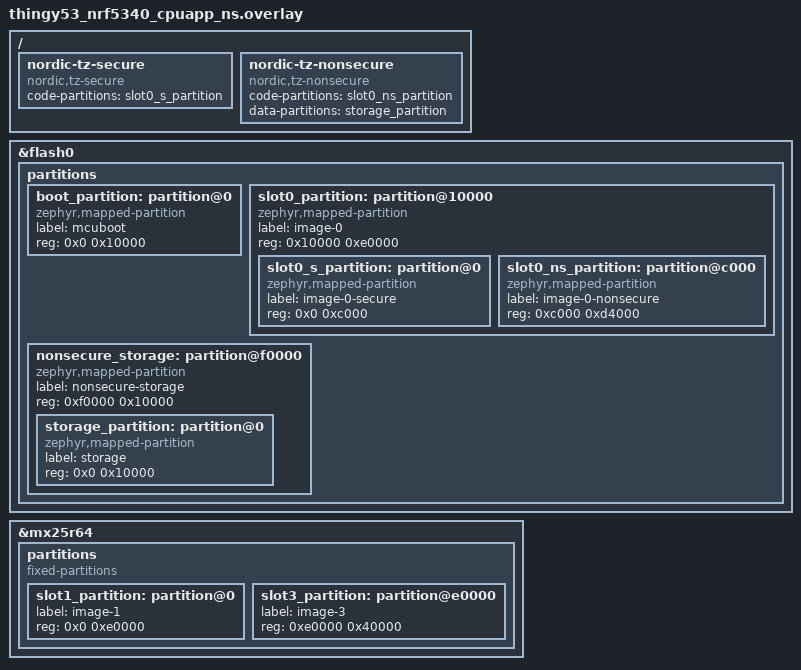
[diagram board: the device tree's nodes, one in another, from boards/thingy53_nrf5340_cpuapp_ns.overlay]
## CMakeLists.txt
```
#
# Copyright (c) 2023 Nordic Semiconductor
#
# SPDX-License-Identifier: LicenseRef-Nordic-5-Clause
#
cmake_minimum_required(VERSION 3.20.0)

find_package(Zephyr REQUIRED HINTS $ENV{ZEPHYR_BASE})
project(NONE)

# NORDIC SDK APP START
target_sources(app PRIVATE
  src/main.c
)

# NORDIC SDK APP END
```

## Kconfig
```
#
# Copyright (c) 2023 Nordic Semiconductor
#
# SPDX-License-Identifier: LicenseRef-Nordic-5-Clause
#

source "Kconfig.zephyr"

menu "Nordic Status Message GATT service sample"

config BT_STATUS_SECURITY_ENABLED
	bool "Enable security"
	default y
	select BT_SMP
	select BT_SETTINGS
	select FLASH
	select FLASH_PAGE_LAYOUT
	select FLASH_MAP
	select ZMS if (SOC_FLASH_NRF_RRAM || SOC_FLASH_NRF_MRAM)
	select NVS if !(SOC_FLASH_NRF_RRAM || SOC_FLASH_NRF_MRAM)
	select SETTINGS
	help
	  Enable BLE security implementation for Nordic Status Message instances.
	  After enabling this option one of the Status Messages would be available only when
	  connection is secure.

endmenu
```

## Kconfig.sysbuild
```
#
# Copyright (c) 2023 Nordic Semiconductor
#
# SPDX-License-Identifier: LicenseRef-Nordic-5-Clause
#

config PARTITION_MANAGER
	default y if BOARD_THINGY53

config NRF_DEFAULT_IPC_RADIO
	default y

source "share/sysbuild/Kconfig"
```

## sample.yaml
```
sample:
  description: Bluetooth Nordic Status Message service sample
  name: Bluetooth LE Nordic Status Message service
common:
  harness: console
  harness_config:
    type: multi_line
    ordered: true
    regex:
      - "Starting Bluetooth Peripheral Status sample"
      - "Bluetooth initialized"
      - "Advertising successfully started"
  timeout: 15
  tags:
    - bluetooth
    - ci_build
    - sysbuild
    - ci_samples_bluetooth
tests:
  sample.bluetooth.peripheral_nsms:
    sysbuild: true
    integration_platforms:
      - nrf54l15dk/nrf54l15/cpuapp
    platform_allow:
      - nrf5340dk/nrf5340/cpuapp
      - nrf5340dk/nrf5340/cpuapp/ns
      - nrf54l15dk/nrf54l05/cpuapp
      - nrf54l15dk/nrf54l10/cpuapp
      - nrf54l15dk/nrf54l15/cpuapp
      - nrf54l15dk/nrf54l15/cpuapp/ns
      - nrf54h20dk/nrf54h20/cpuapp
      - nrf54lm20dk/nrf54lm20a/cpuapp
      - nrf54lm20dk/nrf54lm20a/cpuapp/ns
      - nrf54lm20dk/nrf54lm20b/cpuapp
      - nrf54lm20dk/nrf54lm20b/cpuapp/ns
      - nrf54lv10dk/nrf54lv10a/cpuapp
      - nrf54lv10dk/nrf54lv10a/cpuapp/ns
      - nrf54lc10dk/nrf54lc10a/cpuapp
      - nrf54lc10dk/nrf54lc10a/cpuapp/ns
  sample.bluetooth.peripheral_nsms_no_security:
    sysbuild: true
    extra_args: CONFIG_BT_STATUS_SECURITY_ENABLED=n
    integration_platforms:
      - nrf54l15dk/nrf54l15/cpuapp
    platform_allow:
      - nrf5340dk/nrf5340/cpuapp
      - nrf5340dk/nrf5340/cpuapp/ns
      - nrf54l15dk/nrf54l05/cpuapp
      - nrf54l15dk/nrf54l10/cpuapp
      - nrf54l15dk/nrf54l15/cpuapp
      - nrf54h20dk/nrf54h20/cpuapp
      - nrf54lm20dk/nrf54lm20a/cpuapp
      - nrf54lm20dk/nrf54lm20a/cpuapp/ns
      - nrf54lm20dk/nrf54lm20b/cpuapp
      - nrf54lm20dk/nrf54lm20b/cpuapp/ns
      - nrf54lv10dk/nrf54lv10a/cpuapp
      - nrf54lv10dk/nrf54lv10a/cpuapp/ns
      - nrf54lc10dk/nrf54lc10a/cpuapp
      - nrf54lc10dk/nrf54lc10a/cpuapp/ns
```

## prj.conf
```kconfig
#
# Copyright (c) 2023 Nordic Semiconductor
#
# SPDX-License-Identifier: LicenseRef-Nordic-5-Clause
#
CONFIG_NCS_SAMPLES_DEFAULTS=y

CONFIG_BT=y
CONFIG_BT_PERIPHERAL=y
CONFIG_BT_DEVICE_NAME="Nordic_Status"

# Enable the LBS service
CONFIG_BT_NSMS=y
CONFIG_DK_LIBRARY=y

CONFIG_SYSTEM_WORKQUEUE_STACK_SIZE=2048
```

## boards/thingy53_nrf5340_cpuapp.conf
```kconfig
#
# Copyright (c) 2023 Nordic Semiconductor ASA
#
# SPDX-License-Identifier: LicenseRef-Nordic-5-Clause
#
################################################################################
# Application overlay - Thingy:53 DFU

CONFIG_MCUMGR=y
CONFIG_MCUMGR_TRANSPORT_BT=y
CONFIG_MCUMGR_TRANSPORT_BT_PERM_RW=y
CONFIG_MCUMGR_TRANSPORT_BT_CONN_PARAM_CONTROL=y

CONFIG_MCUMGR_GRP_IMG=y
CONFIG_MCUMGR_GRP_OS=y

# Enable MCUmgr Packet Reassembly feature over Bluetooth and its
# configuration dependencies. MCUmgr buffer size is optimized to fit one SMP
# packet divided into five Bluetooth Write Commands, transmitted with the
# maximum possible MTU value: 498 bytes.
CONFIG_MCUMGR_TRANSPORT_BT_REASSEMBLY=y
CONFIG_MCUMGR_TRANSPORT_NETBUF_SIZE=2475
CONFIG_MCUMGR_GRP_OS_MCUMGR_PARAMS=y

# Enable custom SMP request to erase settings partition.
CONFIG_MCUMGR_GRP_ZBASIC=y
CONFIG_MCUMGR_GRP_ZBASIC_STORAGE_ERASE=y

# Increase system workqueue stack size to prevent stack overflows while handling
# SMP requests.
CONFIG_SYSTEM_WORKQUEUE_STACK_SIZE=4096

CONFIG_BT_L2CAP_TX_MTU=498
CONFIG_BT_BUF_ACL_TX_SIZE=251
CONFIG_BT_BUF_ACL_RX_SIZE=502

# Use connection parameters that ensure quick data transfer
CONFIG_BT_PERIPHERAL_PREF_MIN_INT=6
CONFIG_BT_PERIPHERAL_PREF_MAX_INT=6
CONFIG_BT_PERIPHERAL_PREF_LATENCY=99
CONFIG_BT_PERIPHERAL_PREF_TIMEOUT=400

# Use deferred logging
CONFIG_NCS_SAMPLES_DEFAULTS=n
CONFIG_LOG=y
CONFIG_LOG_PRINTK=y
CONFIG_LOG_PROCESS_THREAD_STACK_SIZE=1024
CONFIG_LOG_PROCESS_THREAD_STARTUP_DELAY_MS=4000
CONFIG_ASSERT=y
CONFIG_ASSERT_NO_COND_INFO=y
CONFIG_ASSERT_NO_MSG_INFO=y
CONFIG_HW_STACK_PROTECTION=y

################################################################################
# Bootloader configuration

CONFIG_BOOTLOADER_MCUBOOT=y
CONFIG_UPDATEABLE_IMAGE_NUMBER=2

CONFIG_IMG_MANAGER=y
CONFIG_MCUBOOT_IMG_MANAGER=y
CONFIG_IMG_ERASE_PROGRESSIVELY=y

################################################################################
# External flash configuration

CONFIG_NORDIC_QSPI_NOR=y
CONFIG_NORDIC_QSPI_NOR_FLASH_LAYOUT_PAGE_SIZE=4096
CONFIG_NORDIC_QSPI_NOR_STACK_WRITE_BUFFER_SIZE=16

################################################################################
# Enable USB CDC ACM

CONFIG_USB_DEVICE_STACK_NEXT=y
CONFIG_CDC_ACM_SERIAL_INITIALIZE_AT_BOOT=y
CONFIG_CDC_ACM_SERIAL_PRODUCT_STRING="Thingy:53 Application"
CONFIG_CDC_ACM_SERIAL_VID=0x1915
CONFIG_CDC_ACM_SERIAL_PID=0x530C
CONFIG_UDC_DRIVER_LOG_LEVEL_ERR=y
CONFIG_USBD_LOG_LEVEL_ERR=y

# Use CDC_ACM0 for logs
CONFIG_LOG_BACKEND_UART=y
CONFIG_USE_SEGGER_RTT=n
CONFIG_LOG_BACKEND_RTT=n
```

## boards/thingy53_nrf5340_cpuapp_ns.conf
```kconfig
#
# Copyright (c) 2023 Nordic Semiconductor ASA
#
# SPDX-License-Identifier: LicenseRef-Nordic-5-Clause
#
################################################################################
# Application overlay - Thingy:53 DFU

CONFIG_MCUMGR=y
CONFIG_MCUMGR_TRANSPORT_BT=y
CONFIG_MCUMGR_TRANSPORT_BT_AUTHEN=n
CONFIG_MCUMGR_TRANSPORT_BT_CONN_PARAM_CONTROL=y

CONFIG_MCUMGR_GRP_IMG=y
CONFIG_MCUMGR_GRP_OS=y

# Enable MCUmgr Packet Reassembly feature over Bluetooth and its
# configuration dependencies. MCUmgr buffer size is optimized to fit one SMP
# packet divided into five Bluetooth Write Commands, transmitted with the
# maximum possible MTU value: 498 bytes.
CONFIG_MCUMGR_TRANSPORT_BT_REASSEMBLY=y
CONFIG_MCUMGR_TRANSPORT_NETBUF_SIZE=2475
CONFIG_MCUMGR_GRP_OS_MCUMGR_PARAMS=y

# Enable custom SMP request to erase settings partition.
CONFIG_MCUMGR_GRP_ZBASIC=y
CONFIG_MCUMGR_GRP_ZBASIC_STORAGE_ERASE=y

# Increase system workqueue stack size to prevent stack overflows while handling
# SMP requests.
CONFIG_SYSTEM_WORKQUEUE_STACK_SIZE=4096

CONFIG_BT_L2CAP_TX_MTU=498
CONFIG_BT_BUF_ACL_TX_SIZE=251
CONFIG_BT_BUF_ACL_RX_SIZE=502

# Use connection parameters that ensure quick data transfer
CONFIG_BT_PERIPHERAL_PREF_MIN_INT=6
CONFIG_BT_PERIPHERAL_PREF_MAX_INT=6
CONFIG_BT_PERIPHERAL_PREF_LATENCY=99
CONFIG_BT_PERIPHERAL_PREF_TIMEOUT=400

# Use deferred logging
CONFIG_NCS_SAMPLES_DEFAULTS=n
CONFIG_LOG=y
CONFIG_LOG_PRINTK=y
CONFIG_LOG_PROCESS_THREAD_STACK_SIZE=1024
CONFIG_LOG_PROCESS_THREAD_STARTUP_DELAY_MS=4000
CONFIG_ASSERT=y
CONFIG_ASSERT_NO_COND_INFO=y
CONFIG_ASSERT_NO_MSG_INFO=y
CONFIG_HW_STACK_PROTECTION=y

################################################################################
# Bootloader configuration

CONFIG_BOOTLOADER_MCUBOOT=y
CONFIG_UPDATEABLE_IMAGE_NUMBER=2

CONFIG_IMG_MANAGER=y
CONFIG_MCUBOOT_IMG_MANAGER=y
CONFIG_IMG_ERASE_PROGRESSIVELY=y

################################################################################
# External flash configuration

CONFIG_NORDIC_QSPI_NOR=y
CONFIG_NORDIC_QSPI_NOR_FLASH_LAYOUT_PAGE_SIZE=4096
CONFIG_NORDIC_QSPI_NOR_STACK_WRITE_BUFFER_SIZE=16

################################################################################
# Enable USB CDC ACM

CONFIG_USB_DEVICE_STACK=y
CONFIG_USB_DEVICE_REMOTE_WAKEUP=n
CONFIG_USB_DEVICE_PRODUCT="Thingy:53 Application"
CONFIG_USB_DEVICE_VID=0x1915
CONFIG_USB_DEVICE_PID=0x530C
CONFIG_USB_CDC_ACM=y
CONFIG_USB_DEVICE_LOG_LEVEL_ERR=y

# Use CDC_ACM0 for logs
CONFIG_LOG_BACKEND_UART=y
CONFIG_USE_SEGGER_RTT=n
CONFIG_LOG_BACKEND_RTT=n
```

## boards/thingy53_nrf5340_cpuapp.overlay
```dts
/*
 * Copyright (c) 2023 Nordic Semiconductor ASA
 *
 * SPDX-License-Identifier: LicenseRef-Nordic-5-Clause
 */

/ {
	chosen {
		nordic,pm-ext-flash = &mx25r64;
	};
};

/ {
	chosen {
		zephyr,console = &cdc_acm_uart0;
	};
};

&zephyr_udc0 {
	cdc_acm_uart0: cdc_acm_uart0 {
		compatible = "zephyr,cdc-acm-uart";
	};
};
```

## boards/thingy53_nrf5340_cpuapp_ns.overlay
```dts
/*
 * Copyright (c) 2026 Nordic Semiconductor ASA
 *
 * SPDX-License-Identifier: LicenseRef-Nordic-5-Clause
 *
 * Memory map for split image with network core update.
 * External slots: slot1 = app secondary, slot3 = netcore secondary.
 */

/delete-node/ &boot_partition;
/delete-node/ &slot0_partition;
/delete-node/ &slot1_partition;
/delete-node/ &tfm_ps_partition;
/delete-node/ &tfm_its_partition;
/delete-node/ &tfm_otp_partition;
/delete-node/ &storage_partition;

&flash0 {
	partitions {
		boot_partition: partition@0 {
			compatible = "zephyr,mapped-partition";
			label = "mcuboot";
			reg = <0x0 0x10000>;
		};

		slot0_partition: partition@10000 {
			compatible = "zephyr,mapped-partition";
			label = "image-0";
			reg = <0x10000 0xe0000>;
			ranges = <0x0 0x10000 0xe0000>;
			#address-cells = <1>;
			#size-cells = <1>;

			slot0_s_partition: partition@0 {
				compatible = "zephyr,mapped-partition";
				label = "image-0-secure";
				reg = <0x0 0xc000>;
			};

			slot0_ns_partition: partition@c000 {
				compatible = "zephyr,mapped-partition";
				label = "image-0-nonsecure";
				reg = <0xc000 0xd4000>;
			};
		};

		nonsecure_storage: partition@f0000 {
			compatible = "zephyr,mapped-partition";
			label = "nonsecure-storage";
			reg = <0xf0000 0x10000>;
			ranges = <0x0 0xf0000 0x10000>;
			#address-cells = <1>;
			#size-cells = <1>;

			storage_partition: partition@0 {
				compatible = "zephyr,mapped-partition";
				label = "storage";
				reg = <0x0 0x10000>;
			};
		};
	};
};

&mx25r64 {
	status = "okay";

	partitions {
		compatible = "fixed-partitions";
		#address-cells = <1>;
		#size-cells = <1>;

		slot1_partition: partition@0 {
			label = "image-1";
			reg = <0x0 0xe0000>;
		};

		slot3_partition: partition@e0000 {
			label = "image-3";
			reg = <0xe0000 0x40000>;
		};
	};
};

/ {
	/delete-node/ nordic-tz-secure;
	/delete-node/ nordic-tz-nonsecure;

	nordic-tz-secure {
		compatible = "nordic,tz-secure";
		code-partitions = <&slot0_s_partition>;
	};

	nordic-tz-nonsecure {
		compatible = "nordic,tz-nonsecure";
		code-partitions = <&slot0_ns_partition>;
		data-partitions = <&storage_partition>;
	};
};
```

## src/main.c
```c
/*
 * Copyright (c) 2023 Nordic Semiconductor ASA
 *
 * SPDX-License-Identifier: LicenseRef-Nordic-5-Clause
 */

#include <zephyr/types.h>
#include <stddef.h>
#include <string.h>
#include <errno.h>
#include <zephyr/sys/printk.h>
#include <zephyr/sys/byteorder.h>
#include <zephyr/kernel.h>
#include <zephyr/drivers/gpio.h>
#include <soc.h>

#include <zephyr/bluetooth/bluetooth.h>
#include <zephyr/bluetooth/hci.h>
#include <zephyr/bluetooth/conn.h>
#include <zephyr/bluetooth/uuid.h>
#include <zephyr/bluetooth/gatt.h>

#include <bluetooth/services/nsms.h>

#include <zephyr/settings/settings.h>

#include <dk_buttons_and_leds.h>

#define DEVICE_NAME             CONFIG_BT_DEVICE_NAME
#define DEVICE_NAME_LEN         (sizeof(DEVICE_NAME) - 1)


#define RUN_STATUS_LED          DK_LED1
#define CON_STATUS_LED          DK_LED2
#define RUN_LED_BLINK_INTERVAL  1000

#define STATUS1_BUTTON             DK_BTN1_MSK
#define STATUS2_BUTTON             DK_BTN2_MSK

static struct k_work adv_work;

/* Implementation of two status characteristics */
BT_NSMS_DEF(nsms_btn1, "Button 1", false, "Unknown", 20);
BT_NSMS_DEF(nsms_btn2, "Button 2", IS_ENABLED(CONFIG_BT_STATUS_SECURITY_ENABLED), "Unknown", 20);


static const struct bt_data ad[] = {
	BT_DATA_BYTES(BT_DATA_FLAGS, (BT_LE_AD_GENERAL | BT_LE_AD_NO_BREDR)),
	BT_DATA(BT_DATA_NAME_COMPLETE, DEVICE_NAME, DEVICE_NAME_LEN),
};

static const struct bt_data sd[] = {
	BT_DATA_BYTES(BT_DATA_UUID128_ALL, BT_UUID_NSMS_VAL),
};

static void adv_work_handler(struct k_work *work)
{
	int err = bt_le_adv_start(BT_LE_ADV_CONN_FAST_2, ad, ARRAY_SIZE(ad), sd, ARRAY_SIZE(sd));

	if (err) {
		printk("Advertising failed to start (err %d)\n", err);
		return;
	}

	printk("Advertising successfully started\n");
}

static void advertising_start(void)
{
	k_work_submit(&adv_work);
}

static void connected(struct bt_conn *conn, uint8_t err)
{
	if (err) {
		printk("Connection failed, err 0x%02x %s\n", err, bt_hci_err_to_str(err));
		return;
	}

	printk("Connected\n");

	dk_set_led_on(CON_STATUS_LED);
}

static void disconnected(struct bt_conn *conn, uint8_t reason)
{
	printk("Disconnected, reason 0x%02x %s\n", reason, bt_hci_err_to_str(reason));

	dk_set_led_off(CON_STATUS_LED);
}

static void recycled_cb(void)
{
	printk("Connection object available from previous conn. Disconnect is complete!\n");
	advertising_start();
}

#if IS_ENABLED(CONFIG_BT_STATUS_SECURITY_ENABLED)
static void security_changed(struct bt_conn *conn, bt_security_t level,
			     enum bt_security_err err)
{
	char addr[BT_ADDR_LE_STR_LEN];

	bt_addr_le_to_str(bt_conn_get_dst(conn), addr, sizeof(addr));

	if (!err) {
		printk("Security changed: %s level %u\n", addr, level);
	} else {
		printk("Security failed: %s level %u err %d %s\n", addr, level, err,
		       bt_security_err_to_str(err));
	}
}
#endif

BT_CONN_CB_DEFINE(conn_callbacks) = {
	.connected        = connected,
	.disconnected     = disconnected,
	.recycled         = recycled_cb,
#if IS_ENABLED(CONFIG_BT_STATUS_SECURITY_ENABLED)
	.security_changed = security_changed,
#endif
};

#if IS_ENABLED(CONFIG_BT_STATUS_SECURITY_ENABLED)
static void auth_passkey_display(struct bt_conn *conn, unsigned int passkey)
{
	char addr[BT_ADDR_LE_STR_LEN];

	bt_addr_le_to_str(bt_conn_get_dst(conn), addr, sizeof(addr));

	printk("Passkey for %s: %06u\n", addr, passkey);
}

static void auth_cancel(struct bt_conn *conn)
{
	char addr[BT_ADDR_LE_STR_LEN];

	bt_addr_le_to_str(bt_conn_get_dst(conn), addr, sizeof(addr));

	printk("Pairing cancelled: %s\n", addr);
}

static void pairing_complete(struct bt_conn *conn, bool bonded)
{
	char addr[BT_ADDR_LE_STR_LEN];

	bt_addr_le_to_str(bt_conn_get_dst(conn), addr, sizeof(addr));

	printk("Pairing completed: %s, bonded: %d\n", addr, bonded);
}

static void pairing_failed(struct bt_conn *conn, enum bt_security_err reason)
{
	char addr[BT_ADDR_LE_STR_LEN];

	bt_addr_le_to_str(bt_conn_get_dst(conn), addr, sizeof(addr));

	printk("Pairing failed conn: %s, reason %d %s\n", addr, reason,
	       bt_security_err_to_str(reason));
}

static struct bt_conn_auth_cb conn_auth_callbacks = {
	.passkey_display = auth_passkey_display,
	.cancel = auth_cancel,
};

static struct bt_conn_auth_info_cb conn_auth_info_callbacks = {
	.pairing_complete = pairing_complete,
	.pairing_failed = pairing_failed
};
#else
static struct bt_conn_auth_cb conn_auth_callbacks;
static struct bt_conn_auth_info_cb conn_auth_info_callbacks;
#endif /* IS_ENABLED(CONFIG_BT_STATUS_SECURITY_ENABLED) */


static void button_changed(uint32_t button_state, uint32_t has_changed)
{
	if (has_changed & STATUS1_BUTTON) {
		bt_nsms_set_status(&nsms_btn1,
				   (button_state & STATUS1_BUTTON) ? "Pressed" : "Released");
	}
	if (has_changed & STATUS2_BUTTON) {
		bt_nsms_set_status(&nsms_btn2,
				   (button_state & STATUS2_BUTTON) ? "Pressed" : "Released");
	}
}

static int init_button(void)
{
	int err;

	err = dk_buttons_init(button_changed);
	if (err) {
		printk("Cannot init buttons (err: %d)\n", err);
	}

	return err;
}

int main(void)
{
	int blink_status = 0;
	int err;

	printk("Starting Bluetooth Peripheral Status sample\n");

	err = dk_leds_init();
	if (err) {
		printk("LEDs init failed (err %d)\n", err);
		return 0;
	}

	err = init_button();
	if (err) {
		printk("Button init failed (err %d)\n", err);
		return 0;
	}

	if (IS_ENABLED(CONFIG_BT_STATUS_SECURITY_ENABLED)) {
		err = bt_conn_auth_cb_register(&conn_auth_callbacks);
		if (err) {
			printk("Failed to register authorization callbacks.\n");
			return 0;
		}

		err = bt_conn_auth_info_cb_register(&conn_auth_info_callbacks);
		if (err) {
			printk("Failed to register authorization info callbacks.\n");
			return 0;
		}
	}

	err = bt_enable(NULL);
	if (err) {
		printk("Bluetooth init failed (err %d)\n", err);
		return 0;
	}

	printk("Bluetooth initialized\n");

	if (IS_ENABLED(CONFIG_SETTINGS)) {
		settings_load();
	}

	k_work_init(&adv_work, adv_work_handler);
	advertising_start();

	for (;;) {
		dk_set_led(RUN_STATUS_LED, (++blink_status) % 2);
		k_sleep(K_MSEC(RUN_LED_BLINK_INTERVAL));
	}
}
```
